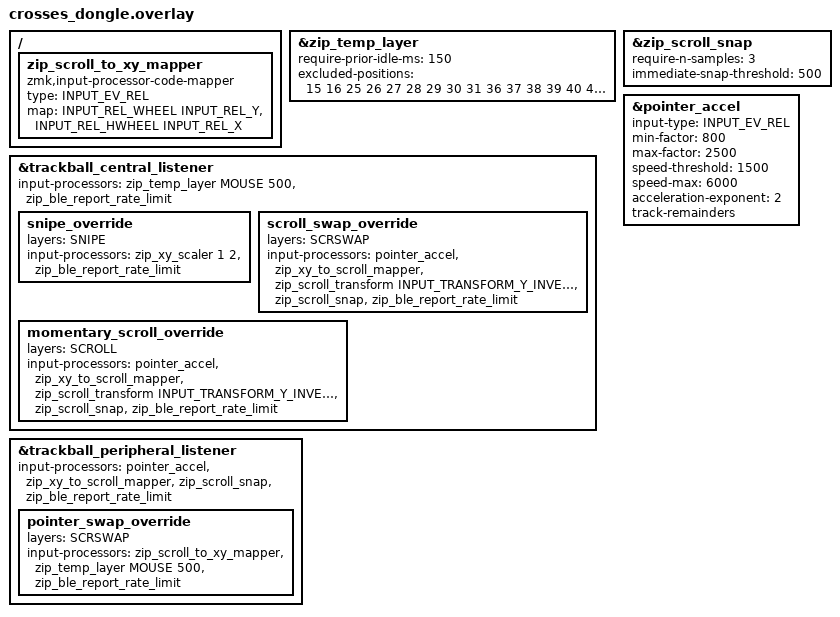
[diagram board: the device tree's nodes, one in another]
#include <scroll-snap.dtsi>
#include <behaviors/input_gestures_accel.dtsi>
#include <zephyr/dt-bindings/input/input-event-codes.h>
#include <dt-bindings/zmk/input_transform.h>

#define MOUSE   9
#define SNIPE   10
#define SCRSWAP 13
#define SCROLL  14

&zip_temp_layer {
    require-prior-idle-ms = <150>;
    excluded-positions = <15 16 25 26 27 28 29 30 31 36 37 38 39 40 41 42 43 44 45 46 48 49 50 51 52 53>;
};

&zip_scroll_snap {
    require-n-samples = <3>;
    immediate-snap-threshold = <500>;
};

/ {
    zip_scroll_to_xy_mapper: zip_scroll_to_xy_mapper {
        compatible = "zmk,input-processor-code-mapper";
        #input-processor-cells = <0>;
        type = <INPUT_EV_REL>;
        map
            = <INPUT_REL_WHEEL INPUT_REL_Y>
            , <INPUT_REL_HWHEEL INPUT_REL_X>
            ;
    };
};

&pointer_accel {
    input-type = <INPUT_EV_REL>;
    min-factor = <800>;
    max-factor = <2500>;
    speed-threshold = <1500>;
    speed-max = <6000>;
    acceleration-exponent = <2>;
    track-remainders;
};

&trackball_central_listener {
    status = "okay";
    input-processors
        = <&zip_temp_layer MOUSE 500>
        , <&zip_ble_report_rate_limit>
        ;

    snipe_override {
        layers = <SNIPE>;
        input-processors
            = <&zip_xy_scaler 1 2>
            , <&zip_ble_report_rate_limit>
            ;
    };

    scroll_swap_override {
        layers = <SCRSWAP>;
        input-processors
            = <&pointer_accel>
            , <&zip_xy_to_scroll_mapper>
            , <&zip_scroll_transform INPUT_TRANSFORM_Y_INVERT>
            , <&zip_scroll_snap>
            , <&zip_ble_report_rate_limit>
            ;
    };

    momentary_scroll_override {
        layers = <SCROLL>;
        input-processors
            = <&pointer_accel>
            , <&zip_xy_to_scroll_mapper>
            , <&zip_scroll_transform INPUT_TRANSFORM_Y_INVERT>
            , <&zip_scroll_snap>
            , <&zip_ble_report_rate_limit>
            ;
    };
};

&trackball_peripheral_listener {
    status = "okay";
    input-processors
        = <&pointer_accel>
        , <&zip_xy_to_scroll_mapper>
        , <&zip_scroll_snap>
        , <&zip_ble_report_rate_limit>
        ;

    pointer_swap_override {
        layers = <SCRSWAP>;
        input-processors
            = <&zip_scroll_to_xy_mapper>
            , <&zip_temp_layer MOUSE 500>
            , <&zip_ble_report_rate_limit>
            ;
    };
};
